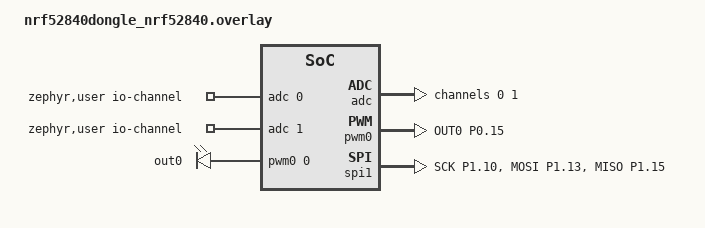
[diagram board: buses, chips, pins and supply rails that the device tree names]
#include <zephyr/dt-bindings/adc/adc.h>
#include <zephyr/dt-bindings/adc/nrf-saadc.h>
#include <zephyr/dt-bindings/pinctrl/nrf-pinctrl.h>

/ {
    /* NOTE: this node name must be zephyr,user (comma!) */
    zephyr,user {
        io-channels = <&adc 0>, <&adc 1>;
    };

    /* Create a convenient alias we can use from C */
    aliases {
        mypwm = &pwm0;
    };

    /* Optional: define a logical "pwm output" node for easier PWM_DT_SPEC_GET */
    pwm_out: pwm_out {
        compatible = "pwm-leds";
        out0: pwm_led_0 {
            pwms = <&pwm0 0 PWM_MSEC(1) PWM_POLARITY_NORMAL>;
        };
    };

    aliases {
        pwmout0 = &out0;
    };
};

&adc {
    status = "okay";
    #address-cells = <1>;
    #size-cells = <0>;

    channel@0 {
        reg = <0>;
        zephyr,gain = "ADC_GAIN_1_6";
        zephyr,reference = "ADC_REF_INTERNAL";
        zephyr,acquisition-time = <ADC_ACQ_TIME_DEFAULT>;
        zephyr,resolution = <12>;
        zephyr,input-positive = <NRF_SAADC_AIN0>; /* P0.02 */
        
        //For differential measurement, use input-negative.
        //Note: this will change the adc range to 0-2000 for 0v - 3V
        //zephyr,input-negative = <NRF_SAADC_GND>;
    };

    channel@1 {
        reg = <1>;
        zephyr,gain = "ADC_GAIN_1_6";
        zephyr,reference = "ADC_REF_INTERNAL";
        zephyr,acquisition-time = <ADC_ACQ_TIME_DEFAULT>;
        zephyr,resolution = <12>;
        zephyr,input-positive = <NRF_SAADC_AIN5>; /* P0.29 */
    };
};

&pwm0 {
    status = "okay";
    pinctrl-0 = <&pwm0_default>;
    pinctrl-1 = <&pwm0_sleep>;
    pinctrl-names = "default", "sleep";
};

&pinctrl {
    pwm0_default: pwm0_default {
        group1 {
            psels = <NRF_PSEL(PWM_OUT0, 0, 15)>; /* PWM0 channel 0 -> P0.15 */
        };
    };

    pwm0_sleep: pwm0_sleep {
        group1 {
            psels = <NRF_PSEL(PWM_OUT0, 0, 15)>;
            low-power-enable;
        };
    };




    spi1_default: spi1_default {
        group1 {
            psels = <
                NRF_PSEL(SPIM_SCK, 1, 10)
                NRF_PSEL(SPIM_MOSI, 1, 13)
                NRF_PSEL(SPIM_MISO, 1, 15)
            >;
        };
    };

    spi1_sleep: spi1_sleep {
        group1 {
            psels = <
                NRF_PSEL(SPIM_SCK, 1, 10)
                NRF_PSEL(SPIM_MOSI, 1, 13)
                NRF_PSEL(SPIM_MISO, 1, 15)
            >;
            low-power-enable;
        };
    };


};




&spi1 {
    status = "okay";
    pinctrl-0 = <&spi1_default>;
    pinctrl-1 = <&spi1_sleep>;
    pinctrl-names = "default", "sleep";
};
